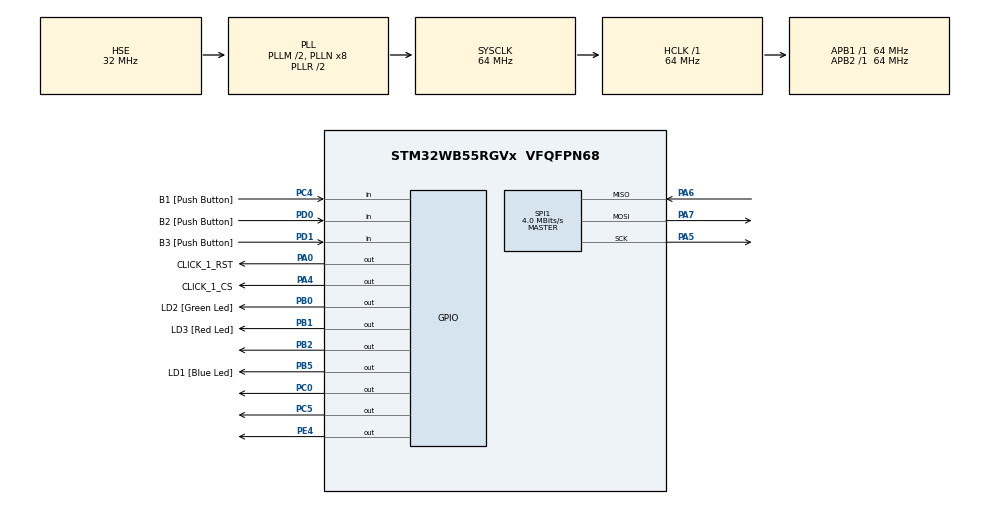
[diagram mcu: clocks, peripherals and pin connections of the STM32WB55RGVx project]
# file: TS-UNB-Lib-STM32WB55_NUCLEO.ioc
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Dma.Request0=SPI1_RX
Dma.Request1=SPI1_TX
Dma.SPI1_RX.0.Direction=DMA_PERIPH_TO_MEMORY
Dma.SPI1_RX.0.EventEnable=DISABLE
Dma.SPI1_RX.0.Instance=DMA1_Channel3
Dma.SPI1_RX.0.MemDataAlignment=DMA_MDATAALIGN_BYTE
Dma.SPI1_RX.0.MemInc=DMA_MINC_ENABLE
Dma.SPI1_RX.0.Mode=DMA_NORMAL
Dma.SPI1_RX.0.PeriphDataAlignment=DMA_PDATAALIGN_BYTE
Dma.SPI1_RX.0.PeriphInc=DMA_PINC_DISABLE
Dma.SPI1_RX.0.Polarity=HAL_DMAMUX_REQ_GEN_RISING
Dma.SPI1_RX.0.Priority=DMA_PRIORITY_LOW
Dma.SPI1_RX.0.RequestNumber=1
Dma.SPI1_RX.0.SignalID=NONE
Dma.SPI1_RX.0.SyncEnable=DISABLE
Dma.SPI1_RX.0.SyncPolarity=HAL_DMAMUX_SYNC_NO_EVENT
Dma.SPI1_RX.0.SyncRequestNumber=1
Dma.SPI1_RX.0.SyncSignalID=NONE
Dma.SPI1_TX.1.Direction=DMA_MEMORY_TO_PERIPH
Dma.SPI1_TX.1.EventEnable=DISABLE
Dma.SPI1_TX.1.Instance=DMA1_Channel4
Dma.SPI1_TX.1.MemDataAlignment=DMA_MDATAALIGN_BYTE
Dma.SPI1_TX.1.MemInc=DMA_MINC_ENABLE
Dma.SPI1_TX.1.Mode=DMA_NORMAL
Dma.SPI1_TX.1.PeriphDataAlignment=DMA_PDATAALIGN_BYTE
Dma.SPI1_TX.1.PeriphInc=DMA_PINC_DISABLE
Dma.SPI1_TX.1.Polarity=HAL_DMAMUX_REQ_GEN_RISING
Dma.SPI1_TX.1.Priority=DMA_PRIORITY_LOW
Dma.SPI1_TX.1.RequestNumber=1
Dma.SPI1_TX.1.SignalID=NONE
Dma.SPI1_TX.1.SyncEnable=DISABLE
Dma.SPI1_TX.1.SyncPolarity=HAL_DMAMUX_SYNC_NO_EVENT
Dma.SPI1_TX.1.SyncRequestNumber=1
Dma.SPI1_TX.1.SyncSignalID=NONE
Mcu.Family=STM32WB
Mcu.Name=STM32WB55RGVx
Mcu.Package=VFQFPN68
NVIC.DMA1_Channel3_IRQn=true\:0\:0\:false\:false\:true\:false\:true\:true
NVIC.DMA1_Channel4_IRQn=true\:0\:0\:false\:false\:true\:false\:true\:true
NVIC.PriorityGroup=NVIC_PRIORITYGROUP_4
NVIC.SPI1_IRQn=true\:1\:0\:true\:false\:true\:true\:true\:true
NVIC.TIM1_UP_TIM16_IRQn=true\:0\:0\:true\:false\:true\:true\:true\:true
OSC_IN.GPIO_Label=RCC_OSC_IN
OSC_IN.Mode=HSE-External-Oscillator
OSC_IN.Signal=RCC_OSC_IN
OSC_OUT.GPIO_Label=RCC_OSC_OUT
OSC_OUT.Mode=HSE-External-Oscillator
OSC_OUT.Signal=RCC_OSC_OUT
PA0.GPIO_Label=CLICK_1_RST
PA0.GPIO_PuPd=GPIO_PULLUP
PA0.GPIO_Speed=GPIO_SPEED_FREQ_HIGH
PA0.PinState=GPIO_PIN_SET
PA0.Signal=GPIO_Output
PA11.GPIO_Label=USB_DM
PA11.Signal=USB_DM
PA12.GPIO_Label=USB_DP
PA12.Signal=USB_DP
PA13.GPIO_Label=JTMS
PA13.Signal=SYS_JTMS-SWDIO
PA14.GPIO_Label=JTCK
PA14.Signal=SYS_JTCK-SWCLK
PA4.GPIO_Label=CLICK_1_CS
PA4.GPIO_PuPd=GPIO_PULLUP
PA4.GPIO_Speed=GPIO_SPEED_FREQ_HIGH
PA4.PinState=GPIO_PIN_SET
PA4.Signal=GPIO_Output
PA5.GPIO_PuPd=GPIO_PULLDOWN
PA5.GPIO_Speed=GPIO_SPEED_FREQ_VERY_HIGH
PA5.Mode=Full_Duplex_Master
PA5.Signal=SPI1_SCK
PA6.GPIO_Speed=GPIO_SPEED_FREQ_VERY_HIGH
PA6.Mode=Full_Duplex_Master
PA6.Signal=SPI1_MISO
PA7.GPIO_PuPd=GPIO_PULLDOWN
PA7.GPIO_Speed=GPIO_SPEED_FREQ_VERY_HIGH
PA7.Mode=Full_Duplex_Master
PA7.Signal=SPI1_MOSI
PB0.GPIO_Label=LD2 [Green Led]
PB0.GPIO_PuPd=GPIO_PULLDOWN
PB0.GPIO_Speed=GPIO_SPEED_FREQ_VERY_HIGH
PB0.Signal=GPIO_Output
PB1.GPIO_Label=LD3 [Red Led]
PB1.GPIO_PuPd=GPIO_PULLDOWN
PB1.GPIO_Speed=GPIO_SPEED_FREQ_VERY_HIGH
PB1.Signal=GPIO_Output
PB2.GPIO_ModeDefaultOutputPP=GPIO_MODE_OUTPUT_PP
PB2.GPIO_PuPd=GPIO_PULLDOWN
PB2.GPIO_Speed=GPIO_SPEED_FREQ_VERY_HIGH
PB2.PinState=GPIO_PIN_RESET
PB2.Signal=GPIO_Output
PB3.GPIO_Label=JTDO
PB3.Signal=SYS_JTDO-SWO
PB5.GPIO_Label=LD1 [Blue Led]
PB5.GPIO_PuPd=GPIO_PULLDOWN
PB5.GPIO_Speed=GPIO_SPEED_FREQ_VERY_HIGH
PB5.Signal=GPIO_Output
PB6.GPIO_Label=STLINK_RX
PB6.Signal=USART1_TX
PB7.GPIO_Label=STLINK_TX
PB7.Signal=USART1_RX
PC0.GPIO_ModeDefaultOutputPP=GPIO_MODE_OUTPUT_PP
PC0.GPIO_PuPd=GPIO_PULLDOWN
PC0.GPIO_Speed=GPIO_SPEED_FREQ_VERY_HIGH
PC0.PinState=GPIO_PIN_RESET
PC0.Signal=GPIO_Output
PC13.GPIO_Label=SYS_WKUP2
PC13.Signal=SYS_WKUP2
PC14-OSC32_IN.GPIO_Label=RCC_OSC32_IN
PC14-OSC32_IN.Mode=LSE-External-Oscillator
PC14-OSC32_IN.Signal=RCC_OSC32_IN
PC15-OSC32_OUT.GPIO_Label=RCC_OSC32_OUT
PC15-OSC32_OUT.Mode=LSE-External-Oscillator
PC15-OSC32_OUT.Signal=RCC_OSC32_OUT
PC4.GPIO_Label=B1 [Push Button]
PC4.Signal=GPIO_Input
PC5.GPIO_ModeDefaultOutputPP=GPIO_MODE_OUTPUT_PP
PC5.GPIO_PuPd=GPIO_PULLDOWN
PC5.GPIO_Speed=GPIO_SPEED_FREQ_VERY_HIGH
PC5.PinState=GPIO_PIN_RESET
PC5.Signal=GPIO_Output
PD0.GPIO_Label=B2 [Push Button]
PD0.Signal=GPIO_Input
PD1.GPIO_Label=B3 [Push Button]
PD1.Signal=GPIO_Input
PE4.GPIO_ModeDefaultOutputPP=GPIO_MODE_OUTPUT_PP
PE4.GPIO_PuPd=GPIO_PULLDOWN
PE4.GPIO_Speed=GPIO_SPEED_FREQ_VERY_HIGH
PE4.PinState=GPIO_PIN_RESET
PE4.Signal=GPIO_Output
ProjectManager.HeapSize=0x200
ProjectManager.StackSize=0x400
ProjectManager.TargetToolchain=STM32CubeIDE
RCC.ADCFreq_Value=64000000
RCC.AHB2CLKDivider=RCC_SYSCLK_DIV2
RCC.AHBFreq_Value=64000000
RCC.APB1Freq_Value=64000000
RCC.APB1TimFreq_Value=64000000
RCC.APB2Freq_Value=64000000
RCC.APB2TimFreq_Value=64000000
RCC.APB3Freq_Value=16000000
RCC.Cortex2_Div=SYSTICK_CLKSOURCE_HCLK_DIV8
RCC.CortexFreq_Value=64000000
RCC.HCLKFreq_Value=64000000
RCC.HSE_VALUE=32000000
RCC.HSI48_VALUE=48000000
RCC.HSI_VALUE=16000000
RCC.PLLM=RCC_PLLM_DIV2
RCC.PLLSourceVirtual=RCC_PLLSOURCE_HSE
RCC.SMPSCLockSelection=RCC_SMPSCLKSOURCE_HSI
RCC.SMPSCLockSelectionVirtual=RCC_SMPSCLKSOURCE_HSI
RCC.SMPSCLockSelectionVirtualVirtual=RCC_SMPSCLKSOURCE_HSI
RCC.SMPSDivider=1
RCC.SYSCLKFreq_VALUE=64000000
RCC.SYSCLKSource=RCC_SYSCLKSOURCE_PLLCLK
RCC.USBFreq_Value=64000000
RCC.VCOOutputFreq_Value=128000000
SPI1.BaudRatePrescaler=SPI_BAUDRATEPRESCALER_16
SPI1.CLKPhase=SPI_PHASE_1EDGE
SPI1.CalculateBaudRate=4.0 MBits/s
SPI1.DataSize=SPI_DATASIZE_8BIT
SPI1.Direction=SPI_DIRECTION_2LINES
SPI1.Mode=SPI_MODE_MASTER
SPI1.VirtualType=VM_MASTER
TIM16.Period=1
TIM16.Prescaler=63
VP_MEMORYMAP_VS_MEMORYMAP.Mode=CurAppReg
VP_TIM16_VS_ClockSourceINT.Mode=Enable_Timer
board=NUCLEO-WB55RG

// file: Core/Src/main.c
/* USER CODE BEGIN Header */
/**
  ******************************************************************************
  * @file           : main.c
  * @brief          : Main program body
  ******************************************************************************
  * @attention
  *
  * Copyright (c) 2024 STMicroelectronics.
  * All rights reserved.
  *
  * This software is licensed under terms that can be found in the LICENSE file
  * in the root directory of this software component.
  * If no LICENSE file comes with this software, it is provided AS-IS.
  *
  ******************************************************************************
  */
/* USER CODE END Header */
#include "main.h"

void SystemClock_Config(void);
void PeriphCommonClock_Config(void);
static void MX_GPIO_Init(void);
static void MX_DMA_Init(void);
static void MX_SPI1_Init(void);
static void MX_TIM16_Init(void);

int main(void)
{

  /* MCU Configuration--------------------------------------------------------*/

  /* Reset of all peripherals, Initializes the Flash interface and the Systick. */
  HAL_Init();

  /* Configure the system clock */
  SystemClock_Config();

  /* Configure the peripherals common clocks */
  PeriphCommonClock_Config();

  /* Initialize all configured peripherals */
  MX_GPIO_Init();
  MX_DMA_Init();
  MX_SPI1_Init();
  MX_TIM16_Init();
  /* USER CODE BEGIN 2 */
  int ItMain( );
  ItMain( );
  /* USER CODE END 2 */

  /* Infinite loop */
  while (1)
  {

  }
}

void SystemClock_Config(void)
{
  RCC_OscInitTypeDef RCC_OscInitStruct = {0};
  RCC_ClkInitTypeDef RCC_ClkInitStruct = {0};

  /** Configure the main internal regulator output voltage
  */
  __HAL_PWR_VOLTAGESCALING_CONFIG(PWR_REGULATOR_VOLTAGE_SCALE1);

  /** Initializes the RCC Oscillators according to the specified parameters
  * in the RCC_OscInitTypeDef structure.
  */
  RCC_OscInitStruct.OscillatorType = RCC_OSCILLATORTYPE_HSI|RCC_OSCILLATORTYPE_HSE;
  RCC_OscInitStruct.HSEState = RCC_HSE_ON;
  RCC_OscInitStruct.HSIState = RCC_HSI_ON;
  RCC_OscInitStruct.HSICalibrationValue = RCC_HSICALIBRATION_DEFAULT;
  RCC_OscInitStruct.PLL.PLLState = RCC_PLL_ON;
  RCC_OscInitStruct.PLL.PLLSource = RCC_PLLSOURCE_HSE;
  RCC_OscInitStruct.PLL.PLLM = RCC_PLLM_DIV2;
  RCC_OscInitStruct.PLL.PLLN = 8;
  RCC_OscInitStruct.PLL.PLLP = RCC_PLLP_DIV2;
  RCC_OscInitStruct.PLL.PLLR = RCC_PLLR_DIV2;
  RCC_OscInitStruct.PLL.PLLQ = RCC_PLLQ_DIV2;
  if (HAL_RCC_OscConfig(&RCC_OscInitStruct) != HAL_OK)
  {
    Error_Handler();
  }

  /** Configure the SYSCLKSource, HCLK, PCLK1 and PCLK2 clocks dividers
  */
  RCC_ClkInitStruct.ClockType = RCC_CLOCKTYPE_HCLK4|RCC_CLOCKTYPE_HCLK2
                              |RCC_CLOCKTYPE_HCLK|RCC_CLOCKTYPE_SYSCLK
                              |RCC_CLOCKTYPE_PCLK1|RCC_CLOCKTYPE_PCLK2;
  RCC_ClkInitStruct.SYSCLKSource = RCC_SYSCLKSOURCE_PLLCLK;
  RCC_ClkInitStruct.AHBCLKDivider = RCC_SYSCLK_DIV1;
  RCC_ClkInitStruct.APB1CLKDivider = RCC_HCLK_DIV1;
  RCC_ClkInitStruct.APB2CLKDivider = RCC_HCLK_DIV1;
  RCC_ClkInitStruct.AHBCLK2Divider = RCC_SYSCLK_DIV2;
  RCC_ClkInitStruct.AHBCLK4Divider = RCC_SYSCLK_DIV1;

  if (HAL_RCC_ClockConfig(&RCC_ClkInitStruct, FLASH_LATENCY_3) != HAL_OK)
  {
    Error_Handler();
  }
}

void PeriphCommonClock_Config(void)
{
  RCC_PeriphCLKInitTypeDef PeriphClkInitStruct = {0};

  /** Initializes the peripherals clock
  */
  PeriphClkInitStruct.PeriphClockSelection = RCC_PERIPHCLK_SMPS;
  PeriphClkInitStruct.SmpsClockSelection = RCC_SMPSCLKSOURCE_HSI;
  PeriphClkInitStruct.SmpsDivSelection = RCC_SMPSCLKDIV_RANGE0;

  if (HAL_RCCEx_PeriphCLKConfig(&PeriphClkInitStruct) != HAL_OK)
  {
    Error_Handler();
  }
}

static void MX_SPI1_Init(void)
{

  LL_SPI_InitTypeDef SPI_InitStruct = {0};

  LL_GPIO_InitTypeDef GPIO_InitStruct = {0};

  /* Peripheral clock enable */
  LL_APB2_GRP1_EnableClock(LL_APB2_GRP1_PERIPH_SPI1);

  LL_AHB2_GRP1_EnableClock(LL_AHB2_GRP1_PERIPH_GPIOA);
  /**SPI1 GPIO Configuration
  PA5   ------> SPI1_SCK
  PA6   ------> SPI1_MISO
  PA7   ------> SPI1_MOSI
  */
  GPIO_InitStruct.Pin = LL_GPIO_PIN_5|LL_GPIO_PIN_7;
  GPIO_InitStruct.Mode = LL_GPIO_MODE_ALTERNATE;
  GPIO_InitStruct.Speed = LL_GPIO_SPEED_FREQ_VERY_HIGH;
  GPIO_InitStruct.OutputType = LL_GPIO_OUTPUT_PUSHPULL;
  GPIO_InitStruct.Pull = LL_GPIO_PULL_DOWN;
  GPIO_InitStruct.Alternate = LL_GPIO_AF_5;
  LL_GPIO_Init(GPIOA, &GPIO_InitStruct);

  GPIO_InitStruct.Pin = LL_GPIO_PIN_6;
  GPIO_InitStruct.Mode = LL_GPIO_MODE_ALTERNATE;
  GPIO_InitStruct.Speed = LL_GPIO_SPEED_FREQ_VERY_HIGH;
  GPIO_InitStruct.OutputType = LL_GPIO_OUTPUT_PUSHPULL;
  GPIO_InitStruct.Pull = LL_GPIO_PULL_NO;
  GPIO_InitStruct.Alternate = LL_GPIO_AF_5;
  LL_GPIO_Init(GPIOA, &GPIO_InitStruct);

  /* SPI1 DMA Init */

  /* SPI1_RX Init */
  LL_DMA_SetPeriphRequest(DMA1, LL_DMA_CHANNEL_3, LL_DMAMUX_REQ_SPI1_RX);

  LL_DMA_SetDataTransferDirection(DMA1, LL_DMA_CHANNEL_3, LL_DMA_DIRECTION_PERIPH_TO_MEMORY);

  LL_DMA_SetChannelPriorityLevel(DMA1, LL_DMA_CHANNEL_3, LL_DMA_PRIORITY_LOW);

  LL_DMA_SetMode(DMA1, LL_DMA_CHANNEL_3, LL_DMA_MODE_NORMAL);

  LL_DMA_SetPeriphIncMode(DMA1, LL_DMA_CHANNEL_3, LL_DMA_PERIPH_NOINCREMENT);

  LL_DMA_SetMemoryIncMode(DMA1, LL_DMA_CHANNEL_3, LL_DMA_MEMORY_INCREMENT);

  LL_DMA_SetPeriphSize(DMA1, LL_DMA_CHANNEL_3, LL_DMA_PDATAALIGN_BYTE);

  LL_DMA_SetMemorySize(DMA1, LL_DMA_CHANNEL_3, LL_DMA_MDATAALIGN_BYTE);

  /* SPI1_TX Init */
  LL_DMA_SetPeriphRequest(DMA1, LL_DMA_CHANNEL_4, LL_DMAMUX_REQ_SPI1_TX);

  LL_DMA_SetDataTransferDirection(DMA1, LL_DMA_CHANNEL_4, LL_DMA_DIRECTION_MEMORY_TO_PERIPH);

  LL_DMA_SetChannelPriorityLevel(DMA1, LL_DMA_CHANNEL_4, LL_DMA_PRIORITY_LOW);

  LL_DMA_SetMode(DMA1, LL_DMA_CHANNEL_4, LL_DMA_MODE_NORMAL);

  LL_DMA_SetPeriphIncMode(DMA1, LL_DMA_CHANNEL_4, LL_DMA_PERIPH_NOINCREMENT);

  LL_DMA_SetMemoryIncMode(DMA1, LL_DMA_CHANNEL_4, LL_DMA_MEMORY_INCREMENT);

  LL_DMA_SetPeriphSize(DMA1, LL_DMA_CHANNEL_4, LL_DMA_PDATAALIGN_BYTE);

  LL_DMA_SetMemorySize(DMA1, LL_DMA_CHANNEL_4, LL_DMA_MDATAALIGN_BYTE);

  /* SPI1 interrupt Init */
  NVIC_SetPriority(SPI1_IRQn, NVIC_EncodePriority(NVIC_GetPriorityGrouping(),1, 0));
  NVIC_EnableIRQ(SPI1_IRQn);

  /* SPI1 parameter configuration*/
  SPI_InitStruct.TransferDirection = LL_SPI_FULL_DUPLEX;
  SPI_InitStruct.Mode = LL_SPI_MODE_MASTER;
  SPI_InitStruct.DataWidth = LL_SPI_DATAWIDTH_8BIT;
  SPI_InitStruct.ClockPolarity = LL_SPI_POLARITY_LOW;
  SPI_InitStruct.ClockPhase = LL_SPI_PHASE_1EDGE;
  SPI_InitStruct.NSS = LL_SPI_NSS_SOFT;
  SPI_InitStruct.BaudRate = LL_SPI_BAUDRATEPRESCALER_DIV16;
  SPI_InitStruct.BitOrder = LL_SPI_MSB_FIRST;
  SPI_InitStruct.CRCCalculation = LL_SPI_CRCCALCULATION_DISABLE;
  SPI_InitStruct.CRCPoly = 7;
  LL_SPI_Init(SPI1, &SPI_InitStruct);
  LL_SPI_SetStandard(SPI1, LL_SPI_PROTOCOL_MOTOROLA);
  LL_SPI_EnableNSSPulseMgt(SPI1);

}

static void MX_TIM16_Init(void)
{

  LL_TIM_InitTypeDef TIM_InitStruct = {0};

  /* Peripheral clock enable */
  LL_APB2_GRP1_EnableClock(LL_APB2_GRP1_PERIPH_TIM16);

  /* TIM16 interrupt Init */
  NVIC_SetPriority(TIM1_UP_TIM16_IRQn, NVIC_EncodePriority(NVIC_GetPriorityGrouping(),0, 0));
  NVIC_EnableIRQ(TIM1_UP_TIM16_IRQn);

  TIM_InitStruct.Prescaler = 63;
  TIM_InitStruct.CounterMode = LL_TIM_COUNTERMODE_UP;
  TIM_InitStruct.Autoreload = 1;
  TIM_InitStruct.ClockDivision = LL_TIM_CLOCKDIVISION_DIV1;
  TIM_InitStruct.RepetitionCounter = 0;
  LL_TIM_Init(TIM16, &TIM_InitStruct);
  LL_TIM_DisableARRPreload(TIM16);

}

static void MX_DMA_Init(void)
{

  /* Init with LL driver */
  /* DMA controller clock enable */
  LL_AHB1_GRP1_EnableClock(LL_AHB1_GRP1_PERIPH_DMAMUX1);
  LL_AHB1_GRP1_EnableClock(LL_AHB1_GRP1_PERIPH_DMA1);

  /* DMA interrupt init */
  /* DMA1_Channel3_IRQn interrupt configuration */
  NVIC_SetPriority(DMA1_Channel3_IRQn, NVIC_EncodePriority(NVIC_GetPriorityGrouping(),0, 0));
  NVIC_EnableIRQ(DMA1_Channel3_IRQn);
  /* DMA1_Channel4_IRQn interrupt configuration */
  NVIC_SetPriority(DMA1_Channel4_IRQn, NVIC_EncodePriority(NVIC_GetPriorityGrouping(),0, 0));
  NVIC_EnableIRQ(DMA1_Channel4_IRQn);

}

static void MX_GPIO_Init(void)
{
  LL_GPIO_InitTypeDef GPIO_InitStruct = {0};

  /* GPIO Ports Clock Enable */
  LL_AHB2_GRP1_EnableClock(LL_AHB2_GRP1_PERIPH_GPIOC);
  LL_AHB2_GRP1_EnableClock(LL_AHB2_GRP1_PERIPH_GPIOA);
  LL_AHB2_GRP1_EnableClock(LL_AHB2_GRP1_PERIPH_GPIOB);
  LL_AHB2_GRP1_EnableClock(LL_AHB2_GRP1_PERIPH_GPIOE);
  LL_AHB2_GRP1_EnableClock(LL_AHB2_GRP1_PERIPH_GPIOD);

  /**/
  LL_GPIO_ResetOutputPin(GPIOC, LL_GPIO_PIN_0|LL_GPIO_PIN_5);

  /**/
  LL_GPIO_ResetOutputPin(GPIOB, LL_GPIO_PIN_2|LD2_Pin|LD3_Pin|LD1_Pin);

  /**/
  LL_GPIO_ResetOutputPin(GPIOE, LL_GPIO_PIN_4);

  /**/
  LL_GPIO_SetOutputPin(GPIOA, CLICK_1_RST_Pin|CLICK_1_CS_Pin);

  /**/
  GPIO_InitStruct.Pin = LL_GPIO_PIN_0|LL_GPIO_PIN_5;
  GPIO_InitStruct.Mode = LL_GPIO_MODE_OUTPUT;
  GPIO_InitStruct.Speed = LL_GPIO_SPEED_FREQ_VERY_HIGH;
  GPIO_InitStruct.OutputType = LL_GPIO_OUTPUT_PUSHPULL;
  GPIO_InitStruct.Pull = LL_GPIO_PULL_DOWN;
  LL_GPIO_Init(GPIOC, &GPIO_InitStruct);

  /**/
  GPIO_InitStruct.Pin = CLICK_1_RST_Pin|CLICK_1_CS_Pin;
  GPIO_InitStruct.Mode = LL_GPIO_MODE_OUTPUT;
  GPIO_InitStruct.Speed = LL_GPIO_SPEED_FREQ_HIGH;
  GPIO_InitStruct.OutputType = LL_GPIO_OUTPUT_PUSHPULL;
  GPIO_InitStruct.Pull = LL_GPIO_PULL_UP;
  LL_GPIO_Init(GPIOA, &GPIO_InitStruct);

  /**/
  GPIO_InitStruct.Pin = B1_Pin;
  GPIO_InitStruct.Mode = LL_GPIO_MODE_INPUT;
  GPIO_InitStruct.Pull = LL_GPIO_PULL_NO;
  LL_GPIO_Init(B1_GPIO_Port, &GPIO_InitStruct);

  /**/
  GPIO_InitStruct.Pin = LL_GPIO_PIN_2|LD2_Pin|LD3_Pin|LD1_Pin;
  GPIO_InitStruct.Mode = LL_GPIO_MODE_OUTPUT;
  GPIO_InitStruct.Speed = LL_GPIO_SPEED_FREQ_VERY_HIGH;
  GPIO_InitStruct.OutputType = LL_GPIO_OUTPUT_PUSHPULL;
  GPIO_InitStruct.Pull = LL_GPIO_PULL_DOWN;
  LL_GPIO_Init(GPIOB, &GPIO_InitStruct);

  /**/
  GPIO_InitStruct.Pin = LL_GPIO_PIN_4;
  GPIO_InitStruct.Mode = LL_GPIO_MODE_OUTPUT;
  GPIO_InitStruct.Speed = LL_GPIO_SPEED_FREQ_VERY_HIGH;
  GPIO_InitStruct.OutputType = LL_GPIO_OUTPUT_PUSHPULL;
  GPIO_InitStruct.Pull = LL_GPIO_PULL_DOWN;
  LL_GPIO_Init(GPIOE, &GPIO_InitStruct);

  /**/
  GPIO_InitStruct.Pin = USB_DM_Pin|USB_DP_Pin;
  GPIO_InitStruct.Mode = LL_GPIO_MODE_ALTERNATE;
  GPIO_InitStruct.Speed = LL_GPIO_SPEED_FREQ_LOW;
  GPIO_InitStruct.OutputType = LL_GPIO_OUTPUT_PUSHPULL;
  GPIO_InitStruct.Pull = LL_GPIO_PULL_NO;
  GPIO_InitStruct.Alternate = LL_GPIO_AF_10;
  LL_GPIO_Init(GPIOA, &GPIO_InitStruct);

  /**/
  GPIO_InitStruct.Pin = B2_Pin|B3_Pin;
  GPIO_InitStruct.Mode = LL_GPIO_MODE_INPUT;
  GPIO_InitStruct.Pull = LL_GPIO_PULL_NO;
  LL_GPIO_Init(GPIOD, &GPIO_InitStruct);

  /**/
  GPIO_InitStruct.Pin = STLINK_RX_Pin|STLINK_TX_Pin;
  GPIO_InitStruct.Mode = LL_GPIO_MODE_ALTERNATE;
  GPIO_InitStruct.Speed = LL_GPIO_SPEED_FREQ_LOW;
  GPIO_InitStruct.OutputType = LL_GPIO_OUTPUT_PUSHPULL;
  GPIO_InitStruct.Pull = LL_GPIO_PULL_NO;
  GPIO_InitStruct.Alternate = LL_GPIO_AF_7;
  LL_GPIO_Init(GPIOB, &GPIO_InitStruct);

}

void Error_Handler(void)
{
  __disable_irq();
  while (1)
  {
  }
}
